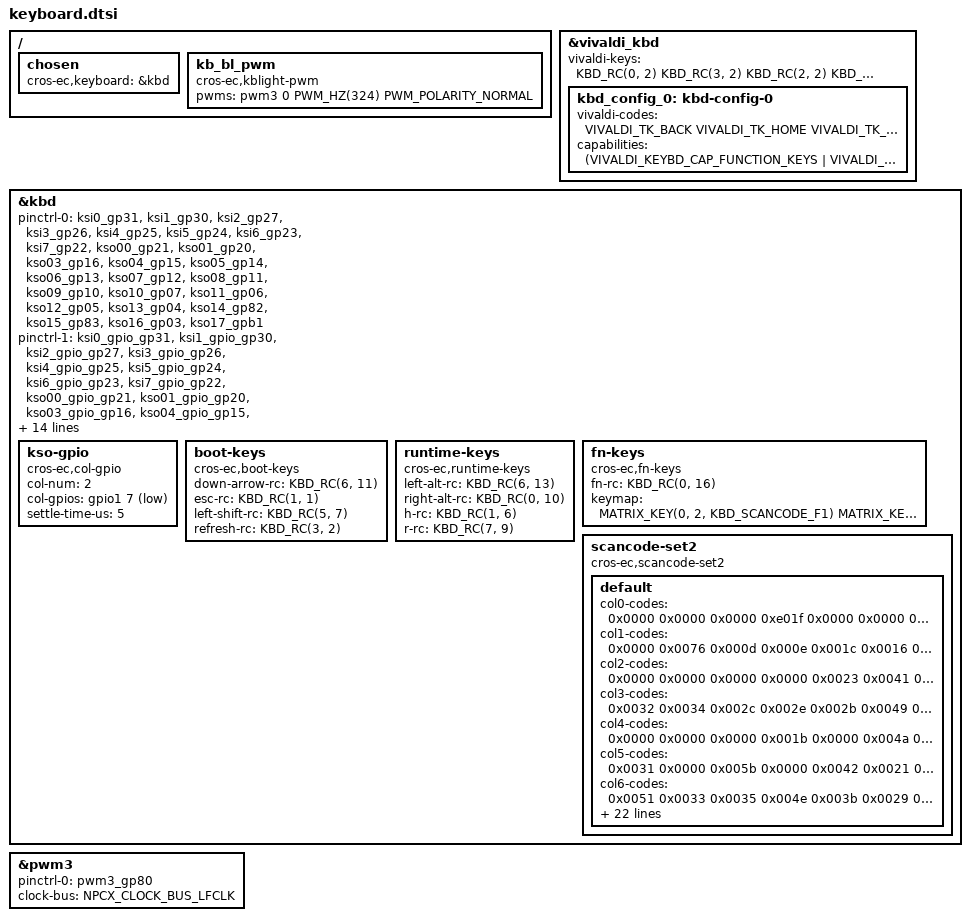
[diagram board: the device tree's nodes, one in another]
/* Copyright 2025 The ChromiumOS Authors
 * Use of this source code is governed by a BSD-style license that can be
 * found in the LICENSE file.
 */

#include <zephyr/dt-bindings/input/keymap.h>

/ {
	chosen {
		cros-ec,keyboard = &kbd;
	};

	kb_bl_pwm {
		compatible = "cros-ec,kblight-pwm";
		pwms = <&pwm3 0 PWM_HZ(324) PWM_POLARITY_NORMAL>;
		status = "okay";
	};
};

&vivaldi_kbd {
	vivaldi-keys = <
		KBD_RC(0, 2)   /* T1 */
		KBD_RC(3, 2)   /* T2 */
		KBD_RC(2, 2)   /* T3 */
		KBD_RC(1, 2)   /* T4 */
		KBD_RC(4, 4)   /* T5 */
		KBD_RC(2, 4)   /* T6 */
		KBD_RC(1, 4)   /* T7 */
		KBD_RC(2, 11)  /* T8 */
		KBD_RC(1, 9)   /* T9 */
		KBD_RC(0, 4)   /* T10 */
		KBD_RC(0, 1)   /* T11 */
		KBD_RC(1, 5)   /* T12 */
		KBD_RC(3, 5)   /* T13 */
		KBD_RC(0, 11)  /* T14 */
	>;

	kbd_config_0: kbd-config-0 {
		vivaldi-codes = <
			VIVALDI_TK_BACK                 /* T1 */
			VIVALDI_TK_HOME                 /* T2 */
			VIVALDI_TK_OVERVIEW             /* T3 */
			VIVALDI_TK_FULLSCREEN           /* T4 */
			VIVALDI_TK_SNAPSHOT             /* T5 */
			VIVALDI_TK_BRIGHTNESS_DOWN      /* T6 */
			VIVALDI_TK_BRIGHTNESS_UP        /* T7 */
			VIVALDI_TK_KBD_BKLIGHT_TOGGLE   /* T8 */
			VIVALDI_TK_MICMUTE              /* T9 */
			VIVALDI_TK_VOL_MUTE             /* T10 */
			VIVALDI_TK_VOL_DOWN             /* T11 */
			VIVALDI_TK_VOL_UP               /* T12 */
			VIVALDI_TK_ACCESSIBILITY        /* T13 */
			VIVALDI_TK_DICTATE              /* T14 */
		>;
		capabilities = <(VIVALDI_KEYBD_CAP_FUNCTION_KEYS |
				VIVALDI_KEYBD_CAP_ASSISTANT_KEY)>;
	};
};

&kbd {
	status = "okay";
	pinctrl-0 = <
		&ksi0_gp31
		&ksi1_gp30
		&ksi2_gp27
		&ksi3_gp26
		&ksi4_gp25
		&ksi5_gp24
		&ksi6_gp23
		&ksi7_gp22
		&kso00_gp21
		&kso01_gp20
		&kso03_gp16
		&kso04_gp15
		&kso05_gp14
		&kso06_gp13
		&kso07_gp12
		&kso08_gp11
		&kso09_gp10
		&kso10_gp07
		&kso11_gp06
		&kso12_gp05
		&kso13_gp04
		&kso14_gp82
		&kso15_gp83
		&kso16_gp03
		&kso17_gpb1
	>;
	pinctrl-1 = <
		&ksi0_gpio_gp31
		&ksi1_gpio_gp30
		&ksi2_gpio_gp27
		&ksi3_gpio_gp26
		&ksi4_gpio_gp25
		&ksi5_gpio_gp24
		&ksi6_gpio_gp23
		&ksi7_gpio_gp22
		&kso00_gpio_gp21
		&kso01_gpio_gp20
		&kso03_gpio_gp16
		&kso04_gpio_gp15
		&kso05_gpio_gp14
		&kso06_gpio_gp13
		&kso07_gpio_gp12
		&kso08_gpio_gp11
		&kso09_gpio_gp10
		&kso10_gpio_gp07
		&kso11_gpio_gp06
		&kso12_gpio_gp05
		&kso13_gpio_gp04
		&kso14_gpio_gp82
		&kso15_gpio_gp83
		&kso16_gpio_gp03
		&kso17_gpio_gpb1
	>;
	pinctrl-names = "default", "sleep";
	row-size = <8>;
	col-size = <18>;
	settle-time-us = <80>;
	debounce-down-ms = <15>;
	debounce-up-ms = <15>;

	actual-key-mask = <
		0x08  /* C0 */
		0xff  /* C1 */
		0xff  /* C2 */
		0xff  /* C3 */
		0xff  /* C4 */
		0xff  /* C5 */
		0xff  /* C6 */
		0xff  /* C7 */
		0xff  /* C8 */
		0xff  /* C9 */
		0xff  /* C10 */
		0xff  /* C11 */
		0xff  /* C12 */
		0x40  /* C13 */
		0x0a  /* C14 */
		0x40  /* C15 */
		0xff  /* C16 */
		0xff  /* C17 */
	>;

	kso-gpio {
		compatible = "cros-ec,col-gpio";
		col-num = <2>;
		col-gpios = <&gpio1 7 GPIO_ACTIVE_LOW>;
		settle-time-us = <5>;
	};

	boot-keys {
		compatible = "cros-ec,boot-keys";
		down-arrow-rc = <KBD_RC(6, 11)>;
		esc-rc = <KBD_RC(1, 1)>;
		left-shift-rc = <KBD_RC(5, 7)>;
		refresh-rc = <KBD_RC(3, 2)>;
	};

	runtime-keys {
		compatible = "cros-ec,runtime-keys";
		left-alt-rc = <KBD_RC(6, 13)>;
		right-alt-rc = <KBD_RC(0, 10)>;
		h-rc = <KBD_RC(1, 6)>;
		r-rc = <KBD_RC(7, 9)>;
	};

	fn-keys {
		compatible = "cros-ec,fn-keys";

		fn-rc = <KBD_RC(0, 16)>;
		keymap = <
			MATRIX_KEY(0, 2, KBD_SCANCODE_F1)
			MATRIX_KEY(3, 2, KBD_SCANCODE_F2)
			MATRIX_KEY(2, 2, KBD_SCANCODE_F3)
			MATRIX_KEY(1, 2, KBD_SCANCODE_F4)
			MATRIX_KEY(4, 4, KBD_SCANCODE_F5)
			MATRIX_KEY(2, 4, KBD_SCANCODE_F6)
			MATRIX_KEY(1, 4, KBD_SCANCODE_F7)
			MATRIX_KEY(2, 11, KBD_SCANCODE_F8)
			MATRIX_KEY(1, 9, KBD_SCANCODE_F9)
			MATRIX_KEY(0, 4, KBD_SCANCODE_F10)
			MATRIX_KEY(0, 1, KBD_SCANCODE_F11)
			MATRIX_KEY(1, 5, KBD_SCANCODE_F12)
			MATRIX_KEY(3, 5, KBD_SCANCODE_F13)
			MATRIX_KEY(0, 11, KBD_SCANCODE_F14)

			MATRIX_KEY(6, 15, KBD_SCANCODE_CAPSLOCK)
			MATRIX_KEY(1, 11, KBD_SCANCODE_DELETE)
			MATRIX_KEY(7, 11, KBD_SCANCODE_PAGEUP)
			MATRIX_KEY(6, 11, KBD_SCANCODE_PAGEDOWN)
			MATRIX_KEY(7, 12, KBD_SCANCODE_HOME)
			MATRIX_KEY(6, 12, KBD_SCANCODE_END)
		>;
	};

	scancode-set2 {
		compatible = "cros-ec,scancode-set2";

		default {
			col0-codes  = <0x0000 0x0000 0x0000 0xe01f 0x0000 0x0000 0x0000 0x0000>;
			col1-codes  = <0x0000 0x0076 0x000d 0x000e 0x001c 0x0016 0x001a 0x003c>;
			col2-codes  = <0x0000 0x0000 0x0000 0x0000 0x0023 0x0041 0x0026 0x0043>;
			col3-codes  = <0x0032 0x0034 0x002c 0x002e 0x002b 0x0049 0x0025 0x0044>;
			col4-codes  = <0x0000 0x0000 0x0000 0x001b 0x0000 0x004a 0x001e 0x004d>;
			col5-codes  = <0x0031 0x0000 0x005b 0x0000 0x0042 0x0021 0x003e 0x0015>;
			col6-codes  = <0x0051 0x0033 0x0035 0x004e 0x003b 0x0029 0x0045 0x001d>;
			col7-codes  = <0x0000 0x0000 0x0000 0x0000 0x0000 0x0012 0x0000 0x0059>;
			col8-codes  = <0x0055 0x0052 0x0054 0x0036 0x004c 0x0022 0x003d 0x0024>;
			col9-codes  = <0xe06c 0x0000 0xe071 0xe05d 0x004b 0x002a 0x0046 0x002d>;
			col10-codes = <0xe011 0x0000 0x0000 0x0000 0x0000 0x0000 0x0000 0x0000>;
			col11-codes = <0x0000 0x0066 0x0000 0x005d 0x005a 0x003a 0xe072 0xe075>;
			col12-codes = <0x0000 0x0064 0xe07d 0x0067 0xe069 0xe07a 0xe074 0xe06b>;
			col13-codes = <0x0000 0x0000 0x0000 0x0000 0x0000 0x0000 0x0011 0x0000>;
			col14-codes = <0x0000 0x0014 0x0000 0xe014 0x0000 0x0000 0x0000 0x0000>;
			col15-codes = <0x0000 0x0000 0x0000 0x0000 0x0000 0x0000 0xe01a 0x0000>;
			col16-codes = <0x0037 0x0000 0x0000 0x0000 0x0000 0x0000 0x0000 0x0000>;
			col17-codes = <0x0000 0x0000 0x006a 0x0000 0x0000 0x0000 0x005d 0x0061>;
		};
	};
};

&pwm3 {
	status = "okay";
	pinctrl-0 = <&pwm3_gp80>;
	pinctrl-names = "default";
	clock-bus = "NPCX_CLOCK_BUS_LFCLK";
};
